# STM32N657 register map
File version: 1.0
CPU: CM55 r0p1, little endian, no MPU, FPU, vendor SysTick, 8 interrupt priority bits
Registers are 32-bit, read-write, reset 0x0 unless marked. A register's access mark holds for its fields unless they carry their own. Offsets are from the block's base; [hi:lo] are bit positions; {n}, {i} and the like mark numbered series.

## TIM2 — General-purpose timers
Base 0x40000000
Same registers: TIM2_S 0x50000000
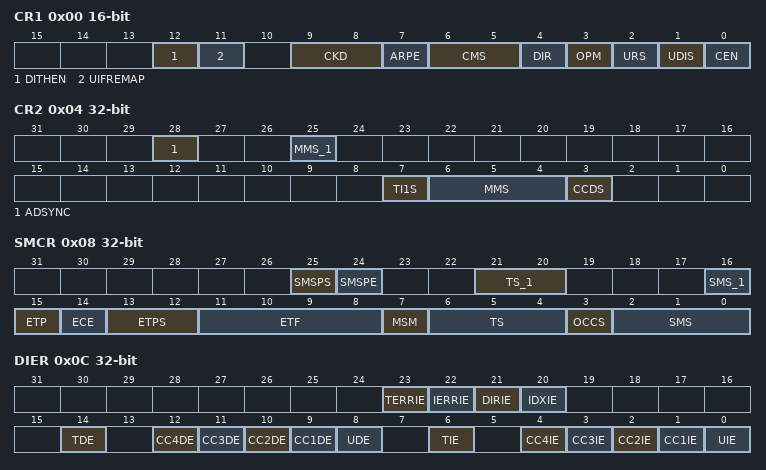
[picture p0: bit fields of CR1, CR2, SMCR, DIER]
0x00 CR1 16-bit — TIM2 control register 1
  [12] DITHEN — Dithering Enable
  [11] UIFREMAP — UIF status bit remapping
  [9:8] CKD — Clock division
  [7] ARPE — Auto-reload preload enable
  [6:5] CMS — Center-aligned mode selection
  [4] DIR — Direction
  [3] OPM — One-pulse mode
  [2] URS — Update request source
  [1] UDIS — Update disable
  [0] CEN — Counter enable
0x04 CR2 — TIM2 control register 2
  [28] ADSYNC — ADC synchronization
  [25] MMS_1 — MMS[3]
  [7] TI1S — tim_ti1 selection
  [6:4] MMS — MMS[0]: Master mode selection
  [3] CCDS — Capture/compare DMA selection
0x08 SMCR — TIM2 slave mode control register
  [25] SMSPS — SMS preload source
  [24] SMSPE — SMS preload enable
  [21:20] TS_1 — TS[4:3]
  [16] SMS_1 — SMS[3]
  [15] ETP — External trigger polarity
  [14] ECE — External clock enable
  [13:12] ETPS — External trigger prescaler
  [11:8] ETF — External trigger filter
  [7] MSM — Master/Slave mode
  [6:4] TS — TS[0]: Trigger selection
  [3] OCCS — OCREF clear selection
  [2:0] SMS — SMS[0]: Slave mode selection
0x0C DIER — TIM2 DMA/Interrupt enable register
  [23] TERRIE — Transition error interrupt enable
  [22] IERRIE — Index error interrupt enable
  [21] DIRIE — Direction change interrupt enable
  [20] IDXIE — Index interrupt enable
  [14] TDE — Trigger DMA request enable
  [n+8] CC{n}DE (n=1..4) — Capture/Compare {n} DMA request enable
  [8] UDE — Update DMA request enable
  [6] TIE — Trigger interrupt enable
  [n] CC{n}IE (n=1..4) — Capture/Compare {n} interrupt enable
  [0] UIE — Update interrupt enable
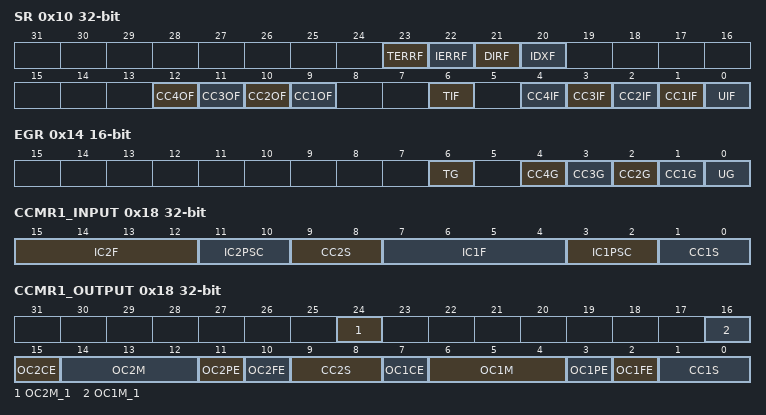
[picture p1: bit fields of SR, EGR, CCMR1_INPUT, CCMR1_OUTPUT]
0x10 SR — TIM2 status register
  [23] TERRF — Transition error interrupt flag
  [22] IERRF — Index error interrupt flag
  [21] DIRF — Direction change interrupt flag
  [20] IDXF — Index interrupt flag
  [12] CC4OF — Capture/Compare 4 overcapture flag
  [11] CC3OF — Capture/Compare 3 overcapture flag
  [10] CC2OF — Capture/compare 2 overcapture flag
  [9] CC1OF — Capture/Compare 1 overcapture flag
  [6] TIF — Trigger interrupt flag
  [4] CC4IF — Capture/Compare 4 interrupt flag
  [3] CC3IF — Capture/Compare 3 interrupt flag
  [2] CC2IF — Capture/Compare 2 interrupt flag
  [1] CC1IF — Capture/compare 1 interrupt flag
  [0] UIF — Update interrupt flag
0x14 EGR 16-bit wo — TIM2 event generation register
  [6] TG — Trigger generation
  [n] CC{n}G (n=1..4) — Capture/compare {n} generation
  [0] UG — Update generation
0x18 CCMR1_INPUT — TIM2 capture/compare mode register 1
  [15:12] IC2F — Input capture 2 filter
  [11:10] IC2PSC — Input capture 2 prescaler
  [9:8] CC2S — Capture/compare 2 selection
  [7:4] IC1F — Input capture 1 filter
  [3:2] IC1PSC — Input capture 1 prescaler
  [1:0] CC1S — Capture/Compare 1 selection
0x18 CCMR1_OUTPUT (alternate view of CCMR1_INPUT) — TIM2 capture/compare mode register 1
  [24] OC2M_1 — OC2M[3]
  [16] OC1M_1 — OC1M[3]
  [15] OC2CE — Output compare 2 clear enable
  [14:12] OC2M — OC2M[2:0]: Output compare 2 mode
  [11] OC2PE — Output compare 2 preload enable
  [10] OC2FE — Output compare 2 fast enable
  [9:8] CC2S — Capture/Compare 2 selection
  [7] OC1CE — Output compare 1 clear enable
  [6:4] OC1M — OC1M[2:0]: Output compare 1 mode
  [3] OC1PE — Output compare 1 preload enable
  [2] OC1FE — Output compare 1 fast enable
  [1:0] CC1S — Capture/Compare 1 selection
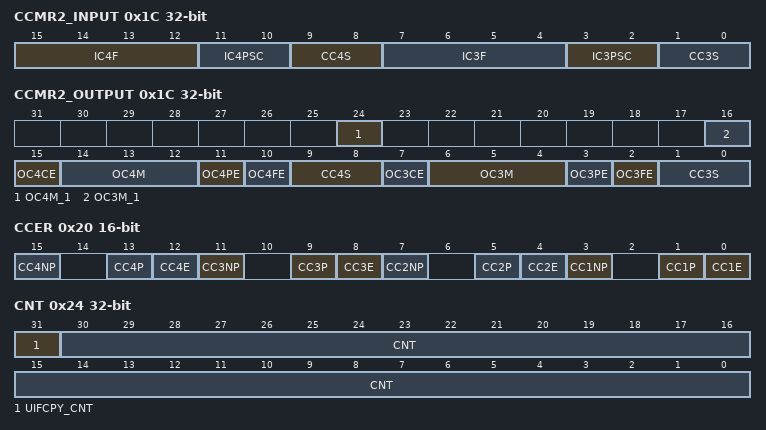
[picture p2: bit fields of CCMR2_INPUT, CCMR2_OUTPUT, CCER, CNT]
0x1C CCMR2_INPUT — TIM2 capture/compare mode register 2
  [15:12] IC4F — Input capture 4 filter
  [11:10] IC4PSC — Input capture 4 prescaler
  [9:8] CC4S — Capture/Compare 4 selection
  [7:4] IC3F — Input capture 3 filter
  [3:2] IC3PSC — Input capture 3 prescaler
  [1:0] CC3S — Capture/Compare 3 selection
0x1C CCMR2_OUTPUT (alternate view of CCMR2_INPUT) — TIM2 capture/compare mode register 2
  [24] OC4M_1 — OC4M[3]
  [16] OC3M_1 — OC3M[3]
  [15] OC4CE — Output compare 4 clear enable
  [14:12] OC4M — OC4M[2:0]: Output compare 4 mode
  [11] OC4PE — Output compare 4 preload enable
  [10] OC4FE — Output compare 4 fast enable
  [9:8] CC4S — Capture/Compare 4 selection
  [7] OC3CE — Output compare 3 clear enable
  [6:4] OC3M — OC3M[2:0]: Output compare 3 mode
  [3] OC3PE — Output compare 3 preload enable
  [2] OC3FE — Output compare 3 fast enable
  [1:0] CC3S — Capture/Compare 3 selection
0x20 CCER 16-bit — TIM2 capture/compare enable register
  [4n-1] CC{n}NP (n=1..4) — Capture/Compare {n} output Polarity.
  [4n-3] CC{n}P (n=1..4) — Capture/Compare {n} output Polarity.
  [4n-4] CC{n}E (n=1..4) — Capture/Compare {n} output enable.
0x24 CNT — TIM2 counter
  [31] UIFCPY_CNT — Value depends on IUFREMAP in TIMx_CR1.
  [30:0] CNT — Least significant part of counter value
0x28 PSC 16-bit — TIM2 prescaler
  [15:0] PSC — Prescaler value
0x2C ARR reset 0xFFFFFFFF — TIM2 auto-reload register
  [31:0] ARR — Auto-reload value
{0x30+4i} CCR{i} (i=1..4) — TIM2 capture/compare register {i}
  [31:0] CCR{i} — Capture/compare {i} value
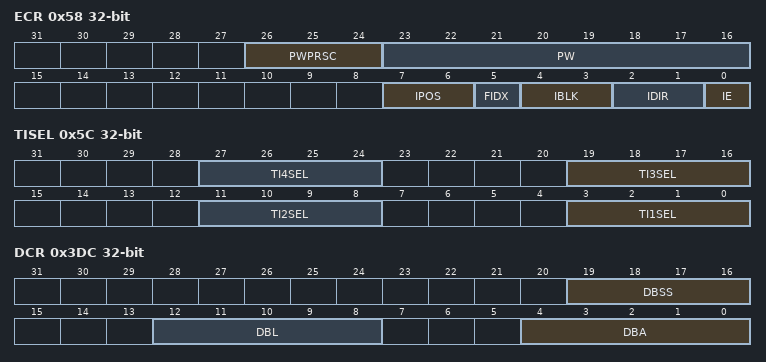
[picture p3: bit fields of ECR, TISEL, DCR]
0x58 ECR — TIM2 timer encoder control register
  [26:24] PWPRSC — Pulse width prescaler
  [23:16] PW — Pulse width
  [7:6] IPOS — Index positioning
  [5] FIDX — First index
  [4:3] IBLK — Index blanking
  [2:1] IDIR — Index direction
  [0] IE — Index enable
0x5C TISEL — TIM2 timer input selection register
  [8n-5:8n-8] TI{n}SEL (n=1..4) — Selects tim_ti{n}[15:0] input
0x60 AF1 — TIM2 alternate function register 1
  [17:14] ETRSEL — etr_in source selection
0x64 AF2 — TIM2 alternate function register 2
  [18:16] OCRSEL — ocref_clr source selection
0x3DC DCR — TIM2 DMA control register
  [19:16] DBSS — DMA burst source selection
  [12:8] DBL — DMA burst length
  [4:0] DBA — DMA base address
0x3E0 DMAR — TIM2 DMA address for full transfer
  [31:0] DMAB — DMA register for burst accesses

## TIM3 — General purpose timers
Base 0x40000400
Same registers: TIM3_S 0x50000400
Registers as TIM2 (with TIM2 read as TIM3).

## TIM4 — General purpose timers
Base 0x40000800
Same registers: TIM4_S 0x50000800
Registers as TIM2 (with TIM2 read as TIM4).

## TIM5 — General purpose timers
Base 0x40000C00
Same registers: TIM5_S 0x50000C00
Registers as TIM2 (with TIM2 read as TIM5).
